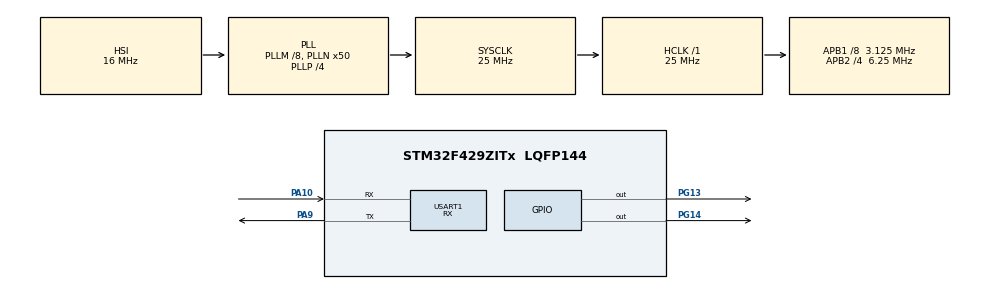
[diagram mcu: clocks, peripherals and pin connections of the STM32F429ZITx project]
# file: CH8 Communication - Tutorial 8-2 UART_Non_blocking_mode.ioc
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Mcu.Family=STM32F4
Mcu.Name=STM32F429ZITx
Mcu.Package=LQFP144
NVIC.PriorityGroup=NVIC_PRIORITYGROUP_1
NVIC.USART1_IRQn=true\:1\:0\:true\:false\:true\:true\:true\:true
PA10.Mode=Asynchronous
PA10.Signal=USART1_RX
PA9.Mode=Asynchronous
PA9.Signal=USART1_TX
PG13.Signal=GPIO_Output
PG14.Signal=GPIO_Output
ProjectManager.HeapSize=0x200
ProjectManager.StackSize=0x400
ProjectManager.TargetToolchain=STM32CubeIDE
RCC.48MHZClocksFreq_Value=14285714.285714285
RCC.AHBFreq_Value=25000000
RCC.APB1CLKDivider=RCC_HCLK_DIV8
RCC.APB1Freq_Value=3125000
RCC.APB1TimFreq_Value=6250000
RCC.APB2CLKDivider=RCC_HCLK_DIV4
RCC.APB2Freq_Value=6250000
RCC.APB2TimFreq_Value=12500000
RCC.CortexFreq_Value=25000000
RCC.HCLKFreq_Value=25000000
RCC.HSE_VALUE=8000000
RCC.HSI_VALUE=16000000
RCC.LSE_VALUE=32768
RCC.PLLM=8
RCC.PLLN=50
RCC.PLLP=RCC_PLLP_DIV4
RCC.PLLQ=7
RCC.SYSCLKFreq_VALUE=25000000
RCC.SYSCLKSource=RCC_SYSCLKSOURCE_PLLCLK
RCC.VCOOutputFreq_Value=100000000
USART1.Mode=MODE_RX
USART1.VirtualMode=VM_ASYNC
board=STM32F429I-DISC1

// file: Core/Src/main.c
/* USER CODE BEGIN Header */
/**
  ******************************************************************************
  * @file           : main.c
  * @brief          : Main program body
  ******************************************************************************
  * @attention
  *
  * Copyright (c) 2023 STMicroelectronics.
  * All rights reserved.
  *
  * This software is licensed under terms that can be found in the LICENSE file
  * in the root directory of this software component.
  * If no LICENSE file comes with this software, it is provided AS-IS.
  *
  ******************************************************************************
  */
	/***************************** Tutorial Tags ******************************
		 UART receive mode only
		 UART with interrupts
		 GPIO Digital outputs
	 **************************************************************************/

	/* 8.2.4 UART Usage in the STM32F4Microcontroller: *************************
	 * Tutorial 8-2: Usage of the UART/USART module in non-blocking operation mode,
	 * the C code

	 In this tutorial, we configure stm32 to receive characters through UART from PC
	 Build the code , so when when the character ’g’ is received,
	 the green LED connected to pin PG13 of the STM32F4 board is toggled. When
	 the character ’r’ is received, the red LED connected to pin PG14 of the STM32F4
	 board is toggled.

	 As the project is compiled and run, the code will wait to receive data from
	 the UART module. To test the code, send the characters ’r’ and ’g’ from the
	 host PC to the STM32F4 microcontroller. Hence, we can observe that the red
	 and green LEDs toggle.
	 ***************************************************************************/
/* USER CODE END Header */
#include "main.h"

UART_HandleTypeDef huart1;

/* USER CODE BEGIN PV */
uint8_t recData;
/* USER CODE END PV */

void SystemClock_Config(void);
static void MX_GPIO_Init(void);
static void MX_USART1_UART_Init(void);

int main(void)
{

  /* MCU Configuration--------------------------------------------------------*/

  /* Reset of all peripherals, Initializes the Flash interface and the Systick. */
  HAL_Init();

  /* Configure the system clock */
  SystemClock_Config();

  /* Initialize all configured peripherals */
  MX_GPIO_Init();
  MX_USART1_UART_Init();
  /* USER CODE BEGIN 2 */
  // Enable UART with interrupt so, the CPU waits to receive something from UART
  // When this happens, when data is received, a callback function is executed
  HAL_UART_Receive_IT(&huart1, &recData, 1);
  /* USER CODE END 2 */

  /* Infinite loop */
  while (1)
  {

  }
}

void SystemClock_Config(void)
{
  RCC_OscInitTypeDef RCC_OscInitStruct = {0};
  RCC_ClkInitTypeDef RCC_ClkInitStruct = {0};

  /** Configure the main internal regulator output voltage
  */
  __HAL_RCC_PWR_CLK_ENABLE();
  __HAL_PWR_VOLTAGESCALING_CONFIG(PWR_REGULATOR_VOLTAGE_SCALE3);

  /** Initializes the RCC Oscillators according to the specified parameters
  * in the RCC_OscInitTypeDef structure.
  */
  RCC_OscInitStruct.OscillatorType = RCC_OSCILLATORTYPE_HSI;
  RCC_OscInitStruct.HSIState = RCC_HSI_ON;
  RCC_OscInitStruct.HSICalibrationValue = RCC_HSICALIBRATION_DEFAULT;
  RCC_OscInitStruct.PLL.PLLState = RCC_PLL_ON;
  RCC_OscInitStruct.PLL.PLLSource = RCC_PLLSOURCE_HSI;
  RCC_OscInitStruct.PLL.PLLM = 8;
  RCC_OscInitStruct.PLL.PLLN = 50;
  RCC_OscInitStruct.PLL.PLLP = RCC_PLLP_DIV4;
  RCC_OscInitStruct.PLL.PLLQ = 7;
  if (HAL_RCC_OscConfig(&RCC_OscInitStruct) != HAL_OK)
  {
    Error_Handler();
  }

  /** Initializes the CPU, AHB and APB buses clocks
  */
  RCC_ClkInitStruct.ClockType = RCC_CLOCKTYPE_HCLK|RCC_CLOCKTYPE_SYSCLK
                              |RCC_CLOCKTYPE_PCLK1|RCC_CLOCKTYPE_PCLK2;
  RCC_ClkInitStruct.SYSCLKSource = RCC_SYSCLKSOURCE_PLLCLK;
  RCC_ClkInitStruct.AHBCLKDivider = RCC_SYSCLK_DIV1;
  RCC_ClkInitStruct.APB1CLKDivider = RCC_HCLK_DIV8;
  RCC_ClkInitStruct.APB2CLKDivider = RCC_HCLK_DIV4;

  if (HAL_RCC_ClockConfig(&RCC_ClkInitStruct, FLASH_LATENCY_0) != HAL_OK)
  {
    Error_Handler();
  }
}

static void MX_USART1_UART_Init(void)
{

  huart1.Instance = USART1;
  huart1.Init.BaudRate = 115200;
  huart1.Init.WordLength = UART_WORDLENGTH_8B;
  huart1.Init.StopBits = UART_STOPBITS_1;
  huart1.Init.Parity = UART_PARITY_NONE;
  huart1.Init.Mode = UART_MODE_RX;
  huart1.Init.HwFlowCtl = UART_HWCONTROL_NONE;
  huart1.Init.OverSampling = UART_OVERSAMPLING_16;
  if (HAL_UART_Init(&huart1) != HAL_OK)
  {
    Error_Handler();
  }

}

static void MX_GPIO_Init(void)
{
  GPIO_InitTypeDef GPIO_InitStruct = {0};

  /* GPIO Ports Clock Enable */
  __HAL_RCC_GPIOA_CLK_ENABLE();
  __HAL_RCC_GPIOG_CLK_ENABLE();

  /*Configure GPIO pin Output Level */
  HAL_GPIO_WritePin(GPIOG, GPIO_PIN_13|GPIO_PIN_14, GPIO_PIN_RESET);

  /*Configure GPIO pins : PG13 PG14 */
  GPIO_InitStruct.Pin = GPIO_PIN_13|GPIO_PIN_14;
  GPIO_InitStruct.Mode = GPIO_MODE_OUTPUT_PP;
  GPIO_InitStruct.Pull = GPIO_NOPULL;
  GPIO_InitStruct.Speed = GPIO_SPEED_FREQ_LOW;
  HAL_GPIO_Init(GPIOG, &GPIO_InitStruct);

}

/* USER CODE BEGIN 4 */
void HAL_UART_RxCpltCallback(UART_HandleTypeDef *huart)
{
	if(recData == 'r')
    HAL_GPIO_TogglePin(GPIOG, GPIO_PIN_13);
	else if (recData == 'g')
	HAL_GPIO_TogglePin(GPIOG, GPIO_PIN_14);
	// __NOP() No operation instruction: consumes clock cycles but does not execute anything.
	// It is mainly used for timing purposes to force memory alignments to prevent hazards, or
	// to occupy a branch delay slot.
	__NOP();
	HAL_UART_Receive_IT(&huart1 , &recData , 1); // Need to put this to generate an interrupt for the next reception of byte
}
/* USER CODE END 4 */

void Error_Handler(void)
{
  __disable_irq();
  while (1)
  {
  }
}
